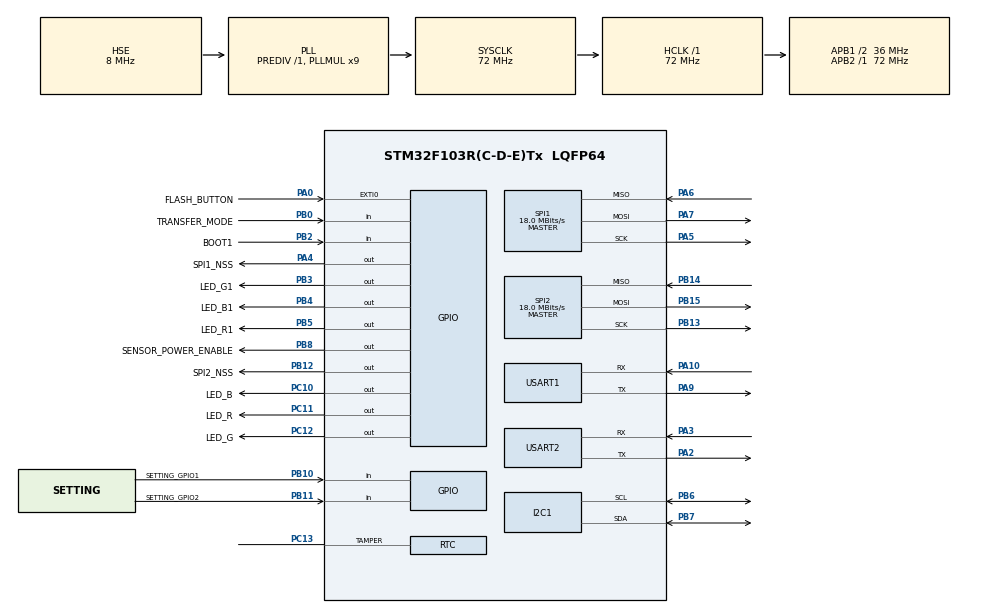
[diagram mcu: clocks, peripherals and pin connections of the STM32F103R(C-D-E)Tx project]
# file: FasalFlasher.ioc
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Mcu.Family=STM32F1
Mcu.Name=STM32F103R(C-D-E)Tx
Mcu.Package=LQFP64
NVIC.PriorityGroup=NVIC_PRIORITYGROUP_4
NVIC.RCC_IRQn=true\:0\:0\:false\:false\:true\:true\:false\:true
NVIC.TIM6_IRQn=true\:0\:0\:false\:false\:true\:true\:true\:true
PA0-WKUP.GPIO_Label=FLASH_BUTTON
PA0-WKUP.Signal=GPXTI0
PA10.Mode=Asynchronous
PA10.Signal=USART1_RX
PA13.Mode=Serial_Wire
PA13.Signal=SYS_JTMS-SWDIO
PA14.Mode=Serial_Wire
PA14.Signal=SYS_JTCK-SWCLK
PA2.Mode=Asynchronous
PA2.Signal=USART2_TX
PA3.Mode=Asynchronous
PA3.Signal=USART2_RX
PA4.GPIO_Label=SPI1_NSS
PA4.Signal=GPIO_Output
PA5.Mode=Full_Duplex_Master
PA5.Signal=SPI1_SCK
PA6.Mode=Full_Duplex_Master
PA6.Signal=SPI1_MISO
PA7.Mode=Full_Duplex_Master
PA7.Signal=SPI1_MOSI
PA9.Mode=Asynchronous
PA9.Signal=USART1_TX
PB0.GPIO_Label=TRANSFER_MODE
PB0.Signal=GPIO_Input
PB10.GPIO_Label=SETTING_GPIO1
PB10.Signal=GPIO_Input
PB11.GPIO_Label=SETTING_GPIO2
PB11.Signal=GPIO_Input
PB12.GPIO_Label=SPI2_NSS
PB12.Signal=GPIO_Output
PB13.Mode=Full_Duplex_Master
PB13.Signal=SPI2_SCK
PB14.Mode=Full_Duplex_Master
PB14.Signal=SPI2_MISO
PB15.Mode=Full_Duplex_Master
PB15.Signal=SPI2_MOSI
PB2.GPIO_Label=BOOT1
PB2.Signal=GPIO_Input
PB3.GPIO_Label=LED_G1
PB3.Signal=GPIO_Output
PB4.GPIO_Label=LED_B1
PB4.Signal=GPIO_Output
PB5.GPIO_Label=LED_R1
PB5.Signal=GPIO_Output
PB6.Mode=I2C
PB6.Signal=I2C1_SCL
PB7.Mode=I2C
PB7.Signal=I2C1_SDA
PB8.GPIO_Label=SENSOR_POWER_ENABLE
PB8.Signal=GPIO_Output
PC10.GPIO_Label=LED_B
PC10.Signal=GPIO_Output
PC11.GPIO_Label=LED_R
PC11.Signal=GPIO_Output
PC12.GPIO_Label=LED_G
PC12.Signal=GPIO_Output
PC13-TAMPER-RTC.Mode=Tamper
PC13-TAMPER-RTC.Signal=RTC_TAMPER
PC14-OSC32_IN.Mode=LSE-External-Oscillator
PC14-OSC32_IN.Signal=RCC_OSC32_IN
PC15-OSC32_OUT.Mode=LSE-External-Oscillator
PC15-OSC32_OUT.Signal=RCC_OSC32_OUT
PD0-OSC_IN.Mode=HSE-External-Oscillator
PD0-OSC_IN.Signal=RCC_OSC_IN
PD1-OSC_OUT.Mode=HSE-External-Oscillator
PD1-OSC_OUT.Signal=RCC_OSC_OUT
ProjectManager.HeapSize=0x100
ProjectManager.StackSize=0x1000
ProjectManager.TargetToolchain=STM32CubeIDE
RCC.AHBFreq_Value=72000000
RCC.APB1CLKDivider=RCC_HCLK_DIV2
RCC.APB1Freq_Value=36000000
RCC.APB1TimFreq_Value=72000000
RCC.APB2Freq_Value=72000000
RCC.APB2TimFreq_Value=72000000
RCC.HCLKFreq_Value=72000000
RCC.PLLMUL=RCC_PLL_MUL9
RCC.PLLSourceVirtual=RCC_PLLSOURCE_HSE
RCC.RTCClockSelection=RCC_RTCCLKSOURCE_LSE
RCC.SYSCLKFreq_VALUE=72000000
RCC.SYSCLKSource=RCC_SYSCLKSOURCE_PLLCLK
RCC.USBFreq_Value=48000000
RCC.USBPrescaler=RCC_USBCLKSOURCE_PLL_DIV1_5
SPI1.BaudRatePrescaler=SPI_BAUDRATEPRESCALER_4
SPI1.CalculateBaudRate=18.0 MBits/s
SPI1.Direction=SPI_DIRECTION_2LINES
SPI1.Mode=SPI_MODE_MASTER
SPI1.VirtualType=VM_MASTER
SPI2.BaudRatePrescaler=SPI_BAUDRATEPRESCALER_2
SPI2.CalculateBaudRate=18.0 MBits/s
SPI2.Direction=SPI_DIRECTION_2LINES
SPI2.Mode=SPI_MODE_MASTER
SPI2.VirtualType=VM_MASTER
TIM6.Period=99
TIM6.Prescaler=3199
USART1.VirtualMode=VM_ASYNC
USART2.VirtualMode=VM_ASYNC
VP_CRC_VS_CRC.Mode=CRC_Activate
VP_FATFS_VS_Generic.Mode=User_defined
VP_RTC_VS_RTC_Activate.Mode=RTC_Enabled
VP_TIM6_VS_ClockSourceINT.Mode=Enable_Timer
board=custom

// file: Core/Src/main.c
/* USER CODE BEGIN Header */
/**
  ******************************************************************************
  * @file           : main.c
  * @brief          : Main program body
  ******************************************************************************
  * @attention
  *
  * Copyright (c) 2024 STMicroelectronics.
  * All rights reserved.
  *
  * This software is licensed under terms that can be found in the LICENSE file
  * in the root directory of this software component.
  * If no LICENSE file comes with this software, it is provided AS-IS.
  *
  ******************************************************************************
  */
/* USER CODE END Header */
#include "main.h"
#include "crc.h"
#include "fatfs.h"
#include "i2c.h"
#include "rtc.h"
#include "spi.h"
#include "tim.h"
#include "usart.h"
#include "gpio.h"

/* USER CODE BEGIN Includes */
#include "AppConfiguration.h"
#include "AppFasal.h"
#include "AppInterrupts.h"
#include "AppResetAndError.h"
/* USER CODE END Includes */

void SystemClock_Config(void);

int main(void)
{

  /* MCU Configuration--------------------------------------------------------*/

  /* Reset of all peripherals, Initializes the Flash interface and the Systick. */
  HAL_Init();

  /* Configure the system clock */
  SystemClock_Config();

  /* Initialize all configured peripherals */
  MX_GPIO_Init();
  MX_CRC_Init();
  MX_I2C1_Init();
  MX_RTC_Init();
  MX_SPI1_Init();
  MX_SPI2_Init();
  MX_USART1_UART_Init();
  MX_USART2_UART_Init();
  MX_FATFS_Init();
  MX_TIM6_Init();

  /* Infinite loop */
  /* USER CODE BEGIN WHILE */
  while (1)
  {
	  AppFasal_Run();
    /* USER CODE END WHILE */

  }
}

void SystemClock_Config(void)
{
  RCC_OscInitTypeDef RCC_OscInitStruct = {0};
  RCC_ClkInitTypeDef RCC_ClkInitStruct = {0};
  RCC_PeriphCLKInitTypeDef PeriphClkInit = {0};

  /** Initializes the RCC Oscillators according to the specified parameters
  * in the RCC_OscInitTypeDef structure.
  */
  RCC_OscInitStruct.OscillatorType = RCC_OSCILLATORTYPE_HSE|RCC_OSCILLATORTYPE_LSE;
  RCC_OscInitStruct.HSEState = RCC_HSE_ON;
  RCC_OscInitStruct.HSEPredivValue = RCC_HSE_PREDIV_DIV1;
  RCC_OscInitStruct.LSEState = RCC_LSE_ON;
  RCC_OscInitStruct.HSIState = RCC_HSI_ON;
  RCC_OscInitStruct.PLL.PLLState = RCC_PLL_ON;
  RCC_OscInitStruct.PLL.PLLSource = RCC_PLLSOURCE_HSE;
  RCC_OscInitStruct.PLL.PLLMUL = RCC_PLL_MUL9;
  if (HAL_RCC_OscConfig(&RCC_OscInitStruct) != HAL_OK)
  {
    Error_Handler();
  }

  /** Initializes the CPU, AHB and APB buses clocks
  */
  RCC_ClkInitStruct.ClockType = RCC_CLOCKTYPE_HCLK|RCC_CLOCKTYPE_SYSCLK
                              |RCC_CLOCKTYPE_PCLK1|RCC_CLOCKTYPE_PCLK2;
  RCC_ClkInitStruct.SYSCLKSource = RCC_SYSCLKSOURCE_PLLCLK;
  RCC_ClkInitStruct.AHBCLKDivider = RCC_SYSCLK_DIV1;
  RCC_ClkInitStruct.APB1CLKDivider = RCC_HCLK_DIV2;
  RCC_ClkInitStruct.APB2CLKDivider = RCC_HCLK_DIV1;

  if (HAL_RCC_ClockConfig(&RCC_ClkInitStruct, FLASH_LATENCY_2) != HAL_OK)
  {
    Error_Handler();
  }
  PeriphClkInit.PeriphClockSelection = RCC_PERIPHCLK_RTC;
  PeriphClkInit.RTCClockSelection = RCC_RTCCLKSOURCE_LSE;
  if (HAL_RCCEx_PeriphCLKConfig(&PeriphClkInit) != HAL_OK)
  {
    Error_Handler();
  }
}

void Error_Handler(void)
{
  /* USER CODE BEGIN Error_Handler_Debug */
  /* User can add his own implementation to report the HAL error return state */
	AppISR_HALErrorHandler();
  /* USER CODE END Error_Handler_Debug */
}

#ifdef  USE_FULL_ASSERT
/**
  * @brief  Reports the name of the source file and the source line number
  *         where the assert_param error has occurred.
  * @param  file: pointer to the source file name
  * @param  line: assert_param error line source number
  * @retval None
  */
void assert_failed(uint8_t *file, uint32_t line)
{
  /* USER CODE BEGIN 6 */
	__assert_func((const char*)file, line, "HAL_Function", "NA");
  /* USER CODE END 6 */
}
#endif /* USE_FULL_ASSERT */
